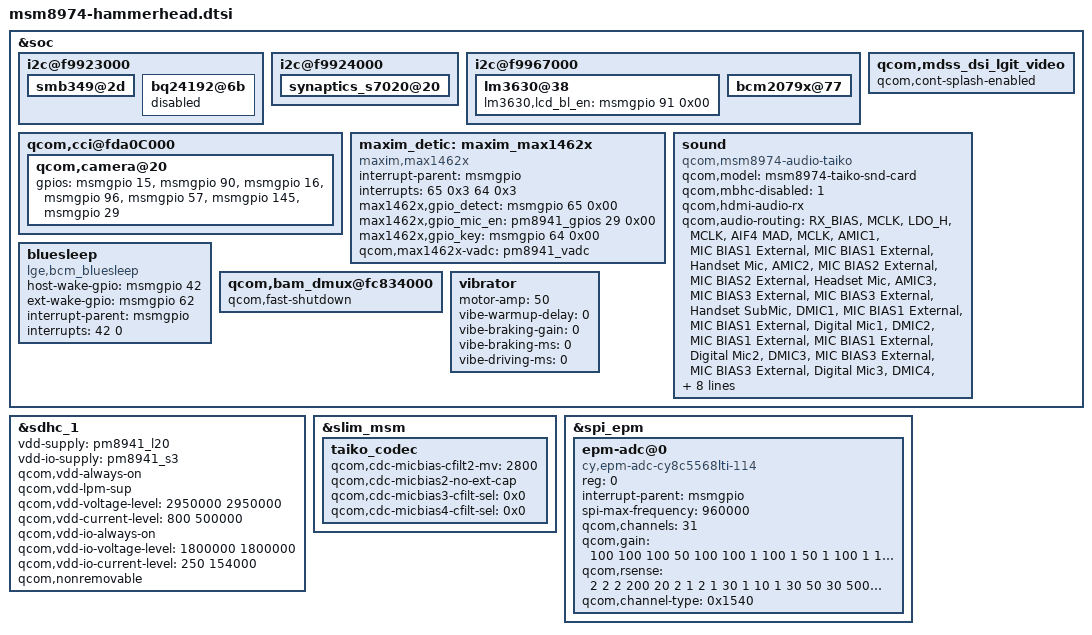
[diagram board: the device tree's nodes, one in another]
/* Copyright (c) 2012, Code Aurora Forum. All rights reserved.
 *
 * This program is free software; you can redistribute it and/or modify
 * it under the terms of the GNU General Public License version 2 and
 * only version 2 as published by the Free Software Foundation.
 *
 * This program is distributed in the hope that it will be useful,
 * but WITHOUT ANY WARRANTY; without even the implied warranty of
 * MERCHANTABILITY or FITNESS FOR A PARTICULAR PURPOSE.  See the
 * GNU General Public License for more details.
 */

#include "msm8974-hammerhead-panel.dtsi"
#include "msm8974-hammerhead-input.dtsi"
#include "msm8974-hammerhead-misc.dtsi"
#include "msm8974-hammerhead-pm.dtsi"
#include "msm8974-hammerhead-usb.dtsi"

&soc {
        i2c@f9923000 {
                smb349@2d {
                        status = "ok";
                };

                bq24192@6b {
                        status = "disabled";
                };
        };

	i2c@f9924000 {
		synaptics_s7020@20 {
			status = "ok";
		};
	};

	i2c@f9967000 {
		lm3630@38 {
			lm3630,lcd_bl_en = <&msmgpio 91 0x00>;
		};
	};

	qcom,cci@fda0C000 {
		qcom,camera@20 {
			gpios = <&msmgpio 15 0>,  // MCLK
			        <&msmgpio 90 0>,  // MAIN_CAM_RESET
				<&msmgpio 16 0>,  // 13M_VANA_EN
				<&msmgpio 96 0>,  // 13M_VIO_EN
				<&msmgpio 57 0>,  // 13M_VCM_EN
				<&msmgpio 145 0>, // OIS_LDO_EN
				<&msmgpio 29 0>;  // OIS_RESET
		};
	};

	qcom,mdss_dsi_lgit_video {
		status = "ok";
		qcom,cont-splash-enabled;
	};

	maxim_detic:maxim_max1462x {
		status = "disabled";
	};

        sound {
		compatible = "qcom,msm8974-audio-taiko";
		qcom,model = "msm8974-taiko-snd-card";

		qcom,mbhc-disabled = <1>;

		qcom,hdmi-audio-rx;

		qcom,audio-routing =
			"RX_BIAS", "MCLK",
			"LDO_H", "MCLK",
			"AIF4 MAD", "MCLK",
			"AMIC1", "MIC BIAS1 External",
			"MIC BIAS1 External", "Handset Mic",
			"AMIC2", "MIC BIAS2 External",
			"MIC BIAS2 External", "Headset Mic",
			"AMIC3", "MIC BIAS3 External",
			"MIC BIAS3 External", "Handset SubMic",
			"DMIC1", "MIC BIAS1 External",
			"MIC BIAS1 External", "Digital Mic1",
			"DMIC2", "MIC BIAS1 External",
			"MIC BIAS1 External", "Digital Mic2",
			"DMIC3", "MIC BIAS3 External",
			"MIC BIAS3 External", "Digital Mic3",
			"DMIC4", "MIC BIAS3 External",
			"MIC BIAS3 External", "Digital Mic4",
			"DMIC5", "MIC BIAS4 External",
			"MIC BIAS4 External", "Digital Mic5",
			"DMIC6", "MIC BIAS4 External",
			"MIC BIAS4 External", "Digital Mic6";

		qcom,cdc-mclk-gpios = <&pm8941_gpios 15 0>;
		taiko-mclk-clk = <&pm8941_clkdiv1>;
		qcom,taiko-mclk-clk-freq = <9600000>;
	};
	
	
	maxim_detic:maxim_max1462x {
		compatible = "maxim,max1462x";
		status = "ok";
		interrupt-parent = <&msmgpio>;
		interrupts = <65 0x3 64 0x3>;
		max1462x,gpio_detect = <&msmgpio 65 0x00>;
		max1462x,gpio_mic_en = <&pm8941_gpios 29 0x00>;
		max1462x,gpio_key = <&msmgpio 64 0x00>;
		qcom,max1462x-vadc = <&pm8941_vadc>;
	};

	i2c@f9967000 {
		bcm2079x@77 {
			status = "ok";
		};
	};

	bluesleep {
		compatible = "lge,bcm_bluesleep";
		host-wake-gpio = <&msmgpio 42 0>;
		ext-wake-gpio = <&msmgpio 62 0>;
		interrupt-parent = <&msmgpio>;
		interrupts = <42 0>;
		interrupt-names = "host_wake";
	};
	
	
	qcom,bam_dmux@fc834000 {
		qcom,fast-shutdown;
	};

	vibrator {
		motor-amp = <50>;
		vibe-warmup-delay = <0>;
		vibe-braking-gain = <0>;
		vibe-braking-ms = <0>;
		vibe-driving-ms = <0>;
	};
};

&sdhc_1 {
	vdd-supply = <&pm8941_l20>;
	vdd-io-supply = <&pm8941_s3>;

	qcom,vdd-always-on;
	qcom,vdd-lpm-sup;
	qcom,vdd-voltage-level = <2950000 2950000>;
	qcom,vdd-current-level = <800 500000>;

	qcom,vdd-io-always-on;
	qcom,vdd-io-voltage-level = <1800000 1800000>;
	qcom,vdd-io-current-level = <250 154000>;

	qcom,nonremovable;
	status = "ok";
};

&slim_msm {
	taiko_codec {
		qcom,cdc-micbias-cfilt2-mv = <2800>;
		qcom,cdc-micbias2-no-ext-cap;
		qcom,cdc-micbias3-cfilt-sel = <0x0>;
		qcom,cdc-micbias4-cfilt-sel = <0x0>;
	};
};

&spi_epm {
	epm-adc@0 {
		compatible = "cy,epm-adc-cy8c5568lti-114";
		reg = <0>;
		interrupt-parent = <&msmgpio>;
		spi-max-frequency = <960000>;
		qcom,channels = <31>;
		qcom,gain = <100 100 100 50 100 100 1 100 1 50
			1 100 1 100 50 50 50 50 50 50
			100 50 100 50 50 50 50 50 50 50
			50>;
		qcom,rsense = <2 2 2 200 20 2 1 2 1 30
			1 10 1 30 50 30 500 30 100 30
			100 500 20 200 1000 20 1000 1000 70 200
			50>;
		qcom,channel-type = <0x1540>;
	};
};
